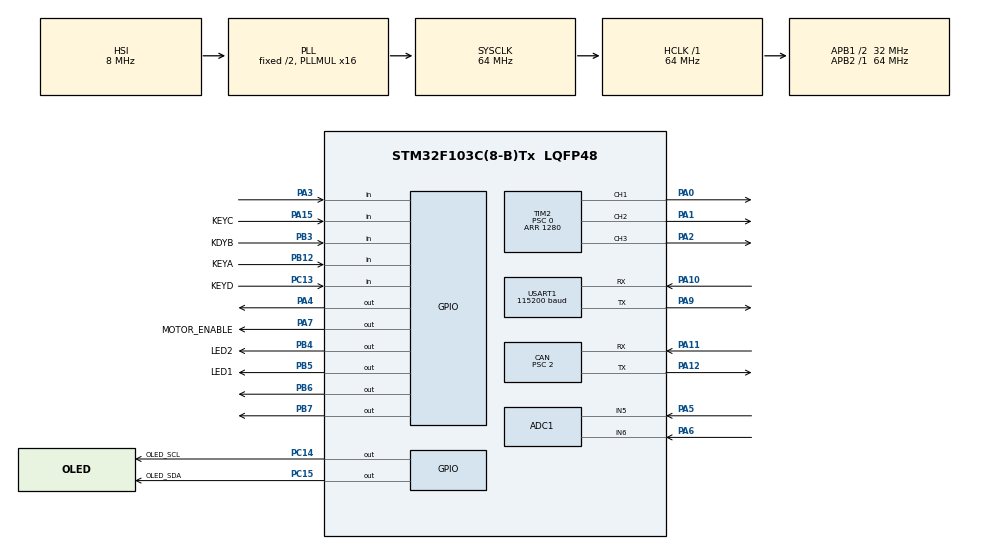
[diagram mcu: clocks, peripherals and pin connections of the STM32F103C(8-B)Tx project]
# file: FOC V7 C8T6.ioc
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ADC1.Channel-0\#ChannelRegularConversion=ADC_CHANNEL_5
ADC1.Channel-1\#ChannelRegularConversion=ADC_CHANNEL_6
ADC1.DiscontinuousConvMode=ENABLE
ADC1.NbrOfConversion=2
ADC1.NbrOfConversionFlag=1
ADC1.Rank-0\#ChannelRegularConversion=1
ADC1.Rank-1\#ChannelRegularConversion=2
ADC1.SamplingTime-0\#ChannelRegularConversion=ADC_SAMPLETIME_13CYCLES_5
ADC1.SamplingTime-1\#ChannelRegularConversion=ADC_SAMPLETIME_13CYCLES_5
ADC1.master=1
CAN.ABOM=ENABLE
CAN.AWUM=DISABLE
CAN.BS1=CAN_BS1_11TQ
CAN.BS2=CAN_BS2_4TQ
CAN.CalculateBaudRate=1000000
CAN.CalculateTimeBit=1000
CAN.CalculateTimeQuantum=62.5
CAN.Mode=CAN_MODE_NORMAL
CAN.NART=ENABLE
CAN.Prescaler=2
CAN.RFLM=DISABLE
CAN.SJW=CAN_SJW_1TQ
CAN.TTCM=DISABLE
CAN.TXFP=DISABLE
Mcu.Family=STM32F1
Mcu.Name=STM32F103C(8-B)Tx
Mcu.Package=LQFP48
NVIC.PriorityGroup=NVIC_PRIORITYGROUP_4
NVIC.TIM1_BRK_IRQn=true\:1\:0\:true\:false\:true\:true\:true\:true
NVIC.TIM1_CC_IRQn=true\:1\:0\:true\:false\:true\:true\:true\:true
NVIC.TIM1_TRG_COM_IRQn=true\:1\:0\:true\:false\:true\:true\:true\:true
NVIC.TIM1_UP_IRQn=true\:1\:0\:true\:false\:true\:true\:true\:true
NVIC.TIM3_IRQn=true\:1\:0\:true\:false\:true\:true\:true\:true
NVIC.USART1_IRQn=true\:0\:0\:false\:false\:true\:true\:true\:true
NVIC.USB_LP_CAN1_RX0_IRQn=true\:1\:0\:true\:false\:true\:true\:true\:true
PA0-WKUP.Signal=S_TIM2_CH1_ETR
PA1.Signal=S_TIM2_CH2
PA10.Mode=Asynchronous
PA10.Signal=USART1_RX
PA11.Mode=CAN_Activate
PA11.Signal=CAN_RX
PA12.Mode=CAN_Activate
PA12.Signal=CAN_TX
PA13.Mode=Serial_Wire
PA13.Signal=SYS_JTMS-SWDIO
PA14.Mode=Serial_Wire
PA14.Signal=SYS_JTCK-SWCLK
PA15.GPIO_Label=KEYC
PA15.GPIO_PuPd=GPIO_PULLUP
PA15.Signal=GPIO_Input
PA2.Signal=S_TIM2_CH3
PA3.GPIO_PuPd=GPIO_PULLUP
PA3.Signal=GPIO_Input
PA4.Signal=GPIO_Output
PA5.Signal=ADCx_IN5
PA6.Signal=ADCx_IN6
PA7.GPIO_Label=MOTOR_ENABLE
PA7.Signal=GPIO_Output
PA9.Mode=Asynchronous
PA9.Signal=USART1_TX
PB12.GPIO_Label=KEYA
PB12.GPIO_PuPd=GPIO_PULLUP
PB12.Signal=GPIO_Input
PB3.GPIO_Label=KDYB
PB3.GPIO_PuPd=GPIO_PULLUP
PB3.Signal=GPIO_Input
PB4.GPIO_Label=LED2
PB4.Signal=GPIO_Output
PB5.GPIO_Label=LED1
PB5.Signal=GPIO_Output
PB6.GPIO_PuPd=GPIO_PULLUP
PB6.GPIO_Speed=GPIO_SPEED_FREQ_HIGH
PB6.PinState=GPIO_PIN_SET
PB6.Signal=GPIO_Output
PB7.GPIO_ModeDefaultOutputPP=GPIO_MODE_OUTPUT_OD
PB7.GPIO_PuPd=GPIO_PULLUP
PB7.GPIO_Speed=GPIO_SPEED_FREQ_HIGH
PB7.PinState=GPIO_PIN_SET
PB7.Signal=GPIO_Output
PC13-TAMPER-RTC.GPIO_Label=KEYD
PC13-TAMPER-RTC.GPIO_PuPd=GPIO_PULLUP
PC13-TAMPER-RTC.Signal=GPIO_Input
PC14-OSC32_IN.GPIO_Label=OLED_SCL
PC14-OSC32_IN.GPIO_Speed=GPIO_SPEED_FREQ_HIGH
PC14-OSC32_IN.Signal=GPIO_Output
PC15-OSC32_OUT.GPIO_Label=OLED_SDA
PC15-OSC32_OUT.GPIO_Speed=GPIO_SPEED_FREQ_HIGH
PC15-OSC32_OUT.Signal=GPIO_Output
ProjectManager.HeapSize=0x200
ProjectManager.StackSize=0x400
ProjectManager.TargetToolchain=MDK-ARM V5.27
RCC.ADCPresc=RCC_ADCPCLK2_DIV6
RCC.AHBFreq_Value=64000000
RCC.APB1CLKDivider=RCC_HCLK_DIV2
RCC.APB1Freq_Value=32000000
RCC.APB1TimFreq_Value=64000000
RCC.APB2Freq_Value=64000000
RCC.APB2TimFreq_Value=64000000
RCC.FLatency=FLASH_LATENCY_2
RCC.HCLKFreq_Value=64000000
RCC.PLLMUL=RCC_PLL_MUL16
RCC.SYSCLKFreq_VALUE=64000000
RCC.SYSCLKSource=RCC_SYSCLKSOURCE_PLLCLK
RCC.USBFreq_Value=64000000
SH.ADCx_IN5.0=ADC1_IN5,IN5
SH.ADCx_IN6.0=ADC1_IN6,IN6
SH.S_TIM2_CH1_ETR.0=TIM2_CH1,PWM Generation1 CH1
SH.S_TIM2_CH2.0=TIM2_CH2,PWM Generation2 CH2
SH.S_TIM2_CH3.0=TIM2_CH3,PWM Generation3 CH3
TIM1.AutoReloadPreload=TIM_AUTORELOAD_PRELOAD_DISABLE
TIM1.ClockDivision=TIM_CLOCKDIVISION_DIV1
TIM1.CounterMode=TIM_COUNTERMODE_UP
TIM1.Period=0
TIM1.Prescaler=64-1
TIM1.TIM_MasterOutputTrigger=TIM_TRGO_RESET
TIM1.TIM_MasterSlaveMode=TIM_MASTERSLAVEMODE_DISABLE
TIM2.AutoReloadPreload=TIM_AUTORELOAD_PRELOAD_DISABLE
TIM2.Channel-PWM\ Generation1\ CH1=TIM_CHANNEL_1
TIM2.Channel-PWM\ Generation2\ CH2=TIM_CHANNEL_2
TIM2.Channel-PWM\ Generation3\ CH3=TIM_CHANNEL_3
TIM2.ClockDivision=TIM_CLOCKDIVISION_DIV1
TIM2.CounterMode=TIM_COUNTERMODE_CENTERALIGNED1
TIM2.OC1Preload_PWM=ENABLE
TIM2.OC2Preload_PWM=ENABLE
TIM2.OC3Preload_PWM=ENABLE
TIM2.OCFastMode_PWM-PWM\ Generation1\ CH1=TIM_OCFAST_DISABLE
TIM2.OCFastMode_PWM-PWM\ Generation2\ CH2=TIM_OCFAST_DISABLE
TIM2.OCFastMode_PWM-PWM\ Generation3\ CH3=TIM_OCFAST_DISABLE
TIM2.OCMode_PWM-PWM\ Generation1\ CH1=TIM_OCMODE_PWM1
TIM2.OCMode_PWM-PWM\ Generation2\ CH2=TIM_OCMODE_PWM1
TIM2.OCMode_PWM-PWM\ Generation3\ CH3=TIM_OCMODE_PWM1
TIM2.OCPolarity_1=TIM_OCPOLARITY_HIGH
TIM2.OCPolarity_2=TIM_OCPOLARITY_HIGH
TIM2.OCPolarity_3=TIM_OCPOLARITY_HIGH
TIM2.Period=1280
TIM2.Prescaler=0
TIM2.Pulse-PWM\ Generation1\ CH1=0
TIM2.Pulse-PWM\ Generation2\ CH2=0
TIM2.Pulse-PWM\ Generation3\ CH3=0
TIM2.TIM_MasterOutputTrigger=TIM_TRGO_RESET
TIM2.TIM_MasterSlaveMode=TIM_MASTERSLAVEMODE_DISABLE
TIM3.Period=100
TIM3.Prescaler=64-1
USART1.BaudRate=115200
USART1.VirtualMode=VM_ASYNC
VP_TIM1_VS_ClockSourceINT.Mode=Internal
VP_TIM2_VS_ClockSourceINT.Mode=Internal
VP_TIM3_VS_ClockSourceINT.Mode=Internal
board=custom

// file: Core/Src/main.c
/* USER CODE BEGIN Header */
/**
  ******************************************************************************
  * @file           : main.c
  * @brief          : Main program body
  ******************************************************************************
  * @attention
  *
  * Copyright (c) 2025 STMicroelectronics.
  * All rights reserved.
  *
  * This software is licensed under terms that can be found in the LICENSE file
  * in the root directory of this software component.
  * If no LICENSE file comes with this software, it is provided AS-IS.
  *
  ******************************************************************************
  */
/* USER CODE END Header */
#include "main.h"

/* USER CODE BEGIN Includes */
#include <stdio.h>
/* USER CODE END Includes */

ADC_HandleTypeDef hadc1;

CAN_HandleTypeDef hcan;

TIM_HandleTypeDef htim1;
TIM_HandleTypeDef htim2;
TIM_HandleTypeDef htim3;

UART_HandleTypeDef huart1;

/* USER CODE BEGIN PV */
int fputc(int ch, FILE* f)
{
	if (ch == '\n')
	{
		/* HAL_UART_Transmit 传入的数据buffer地址，所以需要使用临时变量接�? */
		int tmp = '\r';
		HAL_UART_Transmit(&huart1, (uint8_t*)&tmp, 1, 0xfff);
	}

	HAL_UART_Transmit(&huart1,(uint8_t*)&ch,1,0xfff);

	return (ch);
}
/* USER CODE END PV */

void SystemClock_Config(void);
static void MX_GPIO_Init(void);
static void MX_ADC1_Init(void);
static void MX_CAN_Init(void);
static void MX_TIM1_Init(void);
static void MX_TIM2_Init(void);
static void MX_TIM3_Init(void);
static void MX_USART1_UART_Init(void);

/* USER CODE BEGIN 0 */
#include "nr_micro_shell.h"
/* USER CODE END 0 */

int main(void)
{

  /* MCU Configuration--------------------------------------------------------*/

  /* Reset of all peripherals, Initializes the Flash interface and the Systick. */
  HAL_Init();

  /* Configure the system clock */
  SystemClock_Config();

  /* Initialize all configured peripherals */
  MX_GPIO_Init();
  MX_ADC1_Init();
  MX_CAN_Init();
  MX_TIM1_Init();
  MX_TIM2_Init();
  MX_TIM3_Init();
  MX_USART1_UART_Init();
  /* USER CODE BEGIN 2 */

	printf("hello world \n");
	unsigned int i = 0;

	char test_line[] = "test 1 2 3\n";
	/* 初始 shell */
	shell_init();

	/* 初步测试代码 */
	for(i = 0; i < sizeof(test_line)-1; i++)
	{
		shell(test_line[i]);
	}
  /* USER CODE END 2 */

  /* Infinite loop */
  while (1)
  {

  }
}

void SystemClock_Config(void)
{
  RCC_OscInitTypeDef RCC_OscInitStruct = {0};
  RCC_ClkInitTypeDef RCC_ClkInitStruct = {0};
  RCC_PeriphCLKInitTypeDef PeriphClkInit = {0};

  /** Initializes the RCC Oscillators according to the specified parameters
  * in the RCC_OscInitTypeDef structure.
  */
  RCC_OscInitStruct.OscillatorType = RCC_OSCILLATORTYPE_HSI;
  RCC_OscInitStruct.HSIState = RCC_HSI_ON;
  RCC_OscInitStruct.HSICalibrationValue = RCC_HSICALIBRATION_DEFAULT;
  RCC_OscInitStruct.PLL.PLLState = RCC_PLL_ON;
  RCC_OscInitStruct.PLL.PLLSource = RCC_PLLSOURCE_HSI_DIV2;
  RCC_OscInitStruct.PLL.PLLMUL = RCC_PLL_MUL16;
  if (HAL_RCC_OscConfig(&RCC_OscInitStruct) != HAL_OK)
  {
    Error_Handler();
  }

  /** Initializes the CPU, AHB and APB buses clocks
  */
  RCC_ClkInitStruct.ClockType = RCC_CLOCKTYPE_HCLK|RCC_CLOCKTYPE_SYSCLK
                              |RCC_CLOCKTYPE_PCLK1|RCC_CLOCKTYPE_PCLK2;
  RCC_ClkInitStruct.SYSCLKSource = RCC_SYSCLKSOURCE_PLLCLK;
  RCC_ClkInitStruct.AHBCLKDivider = RCC_SYSCLK_DIV1;
  RCC_ClkInitStruct.APB1CLKDivider = RCC_HCLK_DIV2;
  RCC_ClkInitStruct.APB2CLKDivider = RCC_HCLK_DIV1;

  if (HAL_RCC_ClockConfig(&RCC_ClkInitStruct, FLASH_LATENCY_2) != HAL_OK)
  {
    Error_Handler();
  }
  PeriphClkInit.PeriphClockSelection = RCC_PERIPHCLK_ADC;
  PeriphClkInit.AdcClockSelection = RCC_ADCPCLK2_DIV6;
  if (HAL_RCCEx_PeriphCLKConfig(&PeriphClkInit) != HAL_OK)
  {
    Error_Handler();
  }
}

static void MX_ADC1_Init(void)
{

  ADC_ChannelConfTypeDef sConfig = {0};

  /** Common config
  */
  hadc1.Instance = ADC1;
  hadc1.Init.ScanConvMode = ADC_SCAN_ENABLE;
  hadc1.Init.ContinuousConvMode = DISABLE;
  hadc1.Init.DiscontinuousConvMode = ENABLE;
  hadc1.Init.NbrOfDiscConversion = 1;
  hadc1.Init.ExternalTrigConv = ADC_SOFTWARE_START;
  hadc1.Init.DataAlign = ADC_DATAALIGN_RIGHT;
  hadc1.Init.NbrOfConversion = 2;
  if (HAL_ADC_Init(&hadc1) != HAL_OK)
  {
    Error_Handler();
  }

  /** Configure Regular Channel
  */
  sConfig.Channel = ADC_CHANNEL_5;
  sConfig.Rank = ADC_REGULAR_RANK_1;
  sConfig.SamplingTime = ADC_SAMPLETIME_13CYCLES_5;
  if (HAL_ADC_ConfigChannel(&hadc1, &sConfig) != HAL_OK)
  {
    Error_Handler();
  }

  /** Configure Regular Channel
  */
  sConfig.Channel = ADC_CHANNEL_6;
  sConfig.Rank = ADC_REGULAR_RANK_2;
  if (HAL_ADC_ConfigChannel(&hadc1, &sConfig) != HAL_OK)
  {
    Error_Handler();
  }

}

static void MX_CAN_Init(void)
{

  hcan.Instance = CAN1;
  hcan.Init.Prescaler = 2;
  hcan.Init.Mode = CAN_MODE_NORMAL;
  hcan.Init.SyncJumpWidth = CAN_SJW_1TQ;
  hcan.Init.TimeSeg1 = CAN_BS1_11TQ;
  hcan.Init.TimeSeg2 = CAN_BS2_4TQ;
  hcan.Init.TimeTriggeredMode = DISABLE;
  hcan.Init.AutoBusOff = ENABLE;
  hcan.Init.AutoWakeUp = DISABLE;
  hcan.Init.AutoRetransmission = ENABLE;
  hcan.Init.ReceiveFifoLocked = DISABLE;
  hcan.Init.TransmitFifoPriority = DISABLE;
  if (HAL_CAN_Init(&hcan) != HAL_OK)
  {
    Error_Handler();
  }

}

static void MX_TIM1_Init(void)
{

  TIM_ClockConfigTypeDef sClockSourceConfig = {0};
  TIM_MasterConfigTypeDef sMasterConfig = {0};

  htim1.Instance = TIM1;
  htim1.Init.Prescaler = 64-1;
  htim1.Init.CounterMode = TIM_COUNTERMODE_UP;
  htim1.Init.Period = 0;
  htim1.Init.ClockDivision = TIM_CLOCKDIVISION_DIV1;
  htim1.Init.RepetitionCounter = 0;
  htim1.Init.AutoReloadPreload = TIM_AUTORELOAD_PRELOAD_DISABLE;
  if (HAL_TIM_Base_Init(&htim1) != HAL_OK)
  {
    Error_Handler();
  }
  sClockSourceConfig.ClockSource = TIM_CLOCKSOURCE_INTERNAL;
  if (HAL_TIM_ConfigClockSource(&htim1, &sClockSourceConfig) != HAL_OK)
  {
    Error_Handler();
  }
  sMasterConfig.MasterOutputTrigger = TIM_TRGO_RESET;
  sMasterConfig.MasterSlaveMode = TIM_MASTERSLAVEMODE_DISABLE;
  if (HAL_TIMEx_MasterConfigSynchronization(&htim1, &sMasterConfig) != HAL_OK)
  {
    Error_Handler();
  }

}

static void MX_TIM2_Init(void)
{

  TIM_ClockConfigTypeDef sClockSourceConfig = {0};
  TIM_MasterConfigTypeDef sMasterConfig = {0};
  TIM_OC_InitTypeDef sConfigOC = {0};

  htim2.Instance = TIM2;
  htim2.Init.Prescaler = 0;
  htim2.Init.CounterMode = TIM_COUNTERMODE_CENTERALIGNED1;
  htim2.Init.Period = 1280;
  htim2.Init.ClockDivision = TIM_CLOCKDIVISION_DIV1;
  htim2.Init.AutoReloadPreload = TIM_AUTORELOAD_PRELOAD_DISABLE;
  if (HAL_TIM_Base_Init(&htim2) != HAL_OK)
  {
    Error_Handler();
  }
  sClockSourceConfig.ClockSource = TIM_CLOCKSOURCE_INTERNAL;
  if (HAL_TIM_ConfigClockSource(&htim2, &sClockSourceConfig) != HAL_OK)
  {
    Error_Handler();
  }
  if (HAL_TIM_PWM_Init(&htim2) != HAL_OK)
  {
    Error_Handler();
  }
  sMasterConfig.MasterOutputTrigger = TIM_TRGO_RESET;
  sMasterConfig.MasterSlaveMode = TIM_MASTERSLAVEMODE_DISABLE;
  if (HAL_TIMEx_MasterConfigSynchronization(&htim2, &sMasterConfig) != HAL_OK)
  {
    Error_Handler();
  }
  sConfigOC.OCMode = TIM_OCMODE_PWM1;
  sConfigOC.Pulse = 0;
  sConfigOC.OCPolarity = TIM_OCPOLARITY_HIGH;
  sConfigOC.OCFastMode = TIM_OCFAST_DISABLE;
  if (HAL_TIM_PWM_ConfigChannel(&htim2, &sConfigOC, TIM_CHANNEL_1) != HAL_OK)
  {
    Error_Handler();
  }
  if (HAL_TIM_PWM_ConfigChannel(&htim2, &sConfigOC, TIM_CHANNEL_2) != HAL_OK)
  {
    Error_Handler();
  }
  if (HAL_TIM_PWM_ConfigChannel(&htim2, &sConfigOC, TIM_CHANNEL_3) != HAL_OK)
  {
    Error_Handler();
  }
  HAL_TIM_MspPostInit(&htim2);

}

static void MX_TIM3_Init(void)
{

  TIM_ClockConfigTypeDef sClockSourceConfig = {0};
  TIM_MasterConfigTypeDef sMasterConfig = {0};

  htim3.Instance = TIM3;
  htim3.Init.Prescaler = 64-1;
  htim3.Init.CounterMode = TIM_COUNTERMODE_UP;
  htim3.Init.Period = 100;
  htim3.Init.ClockDivision = TIM_CLOCKDIVISION_DIV1;
  htim3.Init.AutoReloadPreload = TIM_AUTORELOAD_PRELOAD_DISABLE;
  if (HAL_TIM_Base_Init(&htim3) != HAL_OK)
  {
    Error_Handler();
  }
  sClockSourceConfig.ClockSource = TIM_CLOCKSOURCE_INTERNAL;
  if (HAL_TIM_ConfigClockSource(&htim3, &sClockSourceConfig) != HAL_OK)
  {
    Error_Handler();
  }
  sMasterConfig.MasterOutputTrigger = TIM_TRGO_RESET;
  sMasterConfig.MasterSlaveMode = TIM_MASTERSLAVEMODE_DISABLE;
  if (HAL_TIMEx_MasterConfigSynchronization(&htim3, &sMasterConfig) != HAL_OK)
  {
    Error_Handler();
  }

}

static void MX_USART1_UART_Init(void)
{

  huart1.Instance = USART1;
  huart1.Init.BaudRate = 115200;
  huart1.Init.WordLength = UART_WORDLENGTH_8B;
  huart1.Init.StopBits = UART_STOPBITS_1;
  huart1.Init.Parity = UART_PARITY_NONE;
  huart1.Init.Mode = UART_MODE_TX_RX;
  huart1.Init.HwFlowCtl = UART_HWCONTROL_NONE;
  huart1.Init.OverSampling = UART_OVERSAMPLING_16;
  if (HAL_UART_Init(&huart1) != HAL_OK)
  {
    Error_Handler();
  }

}

static void MX_GPIO_Init(void)
{
  GPIO_InitTypeDef GPIO_InitStruct = {0};

  /* GPIO Ports Clock Enable */
  __HAL_RCC_GPIOC_CLK_ENABLE();
  __HAL_RCC_GPIOA_CLK_ENABLE();
  __HAL_RCC_GPIOB_CLK_ENABLE();

  /*Configure GPIO pin Output Level */
  HAL_GPIO_WritePin(GPIOC, OLED_SCL_Pin|OLED_SDA_Pin, GPIO_PIN_RESET);

  /*Configure GPIO pin Output Level */
  HAL_GPIO_WritePin(GPIOA, GPIO_PIN_4|MOTOR_ENABLE_Pin, GPIO_PIN_RESET);

  /*Configure GPIO pin Output Level */
  HAL_GPIO_WritePin(GPIOB, LED2_Pin|LED1_Pin, GPIO_PIN_RESET);

  /*Configure GPIO pin Output Level */
  HAL_GPIO_WritePin(GPIOB, GPIO_PIN_6|GPIO_PIN_7, GPIO_PIN_SET);

  /*Configure GPIO pin : KEYD_Pin */
  GPIO_InitStruct.Pin = KEYD_Pin;
  GPIO_InitStruct.Mode = GPIO_MODE_INPUT;
  GPIO_InitStruct.Pull = GPIO_PULLUP;
  HAL_GPIO_Init(KEYD_GPIO_Port, &GPIO_InitStruct);

  /*Configure GPIO pins : OLED_SCL_Pin OLED_SDA_Pin */
  GPIO_InitStruct.Pin = OLED_SCL_Pin|OLED_SDA_Pin;
  GPIO_InitStruct.Mode = GPIO_MODE_OUTPUT_PP;
  GPIO_InitStruct.Pull = GPIO_NOPULL;
  GPIO_InitStruct.Speed = GPIO_SPEED_FREQ_HIGH;
  HAL_GPIO_Init(GPIOC, &GPIO_InitStruct);

  /*Configure GPIO pins : PA3 KEYC_Pin */
  GPIO_InitStruct.Pin = GPIO_PIN_3|KEYC_Pin;
  GPIO_InitStruct.Mode = GPIO_MODE_INPUT;
  GPIO_InitStruct.Pull = GPIO_PULLUP;
  HAL_GPIO_Init(GPIOA, &GPIO_InitStruct);

  /*Configure GPIO pins : PA4 MOTOR_ENABLE_Pin */
  GPIO_InitStruct.Pin = GPIO_PIN_4|MOTOR_ENABLE_Pin;
  GPIO_InitStruct.Mode = GPIO_MODE_OUTPUT_PP;
  GPIO_InitStruct.Pull = GPIO_NOPULL;
  GPIO_InitStruct.Speed = GPIO_SPEED_FREQ_LOW;
  HAL_GPIO_Init(GPIOA, &GPIO_InitStruct);

  /*Configure GPIO pins : KEYA_Pin KDYB_Pin */
  GPIO_InitStruct.Pin = KEYA_Pin|KDYB_Pin;
  GPIO_InitStruct.Mode = GPIO_MODE_INPUT;
  GPIO_InitStruct.Pull = GPIO_PULLUP;
  HAL_GPIO_Init(GPIOB, &GPIO_InitStruct);

  /*Configure GPIO pins : LED2_Pin LED1_Pin */
  GPIO_InitStruct.Pin = LED2_Pin|LED1_Pin;
  GPIO_InitStruct.Mode = GPIO_MODE_OUTPUT_PP;
  GPIO_InitStruct.Pull = GPIO_NOPULL;
  GPIO_InitStruct.Speed = GPIO_SPEED_FREQ_LOW;
  HAL_GPIO_Init(GPIOB, &GPIO_InitStruct);

  /*Configure GPIO pin : PB6 */
  GPIO_InitStruct.Pin = GPIO_PIN_6;
  GPIO_InitStruct.Mode = GPIO_MODE_OUTPUT_PP;
  GPIO_InitStruct.Pull = GPIO_PULLUP;
  GPIO_InitStruct.Speed = GPIO_SPEED_FREQ_HIGH;
  HAL_GPIO_Init(GPIOB, &GPIO_InitStruct);

  /*Configure GPIO pin : PB7 */
  GPIO_InitStruct.Pin = GPIO_PIN_7;
  GPIO_InitStruct.Mode = GPIO_MODE_OUTPUT_OD;
  GPIO_InitStruct.Pull = GPIO_PULLUP;
  GPIO_InitStruct.Speed = GPIO_SPEED_FREQ_HIGH;
  HAL_GPIO_Init(GPIOB, &GPIO_InitStruct);

}

void Error_Handler(void)
{
  __disable_irq();
  while (1)
  {
  }
}
